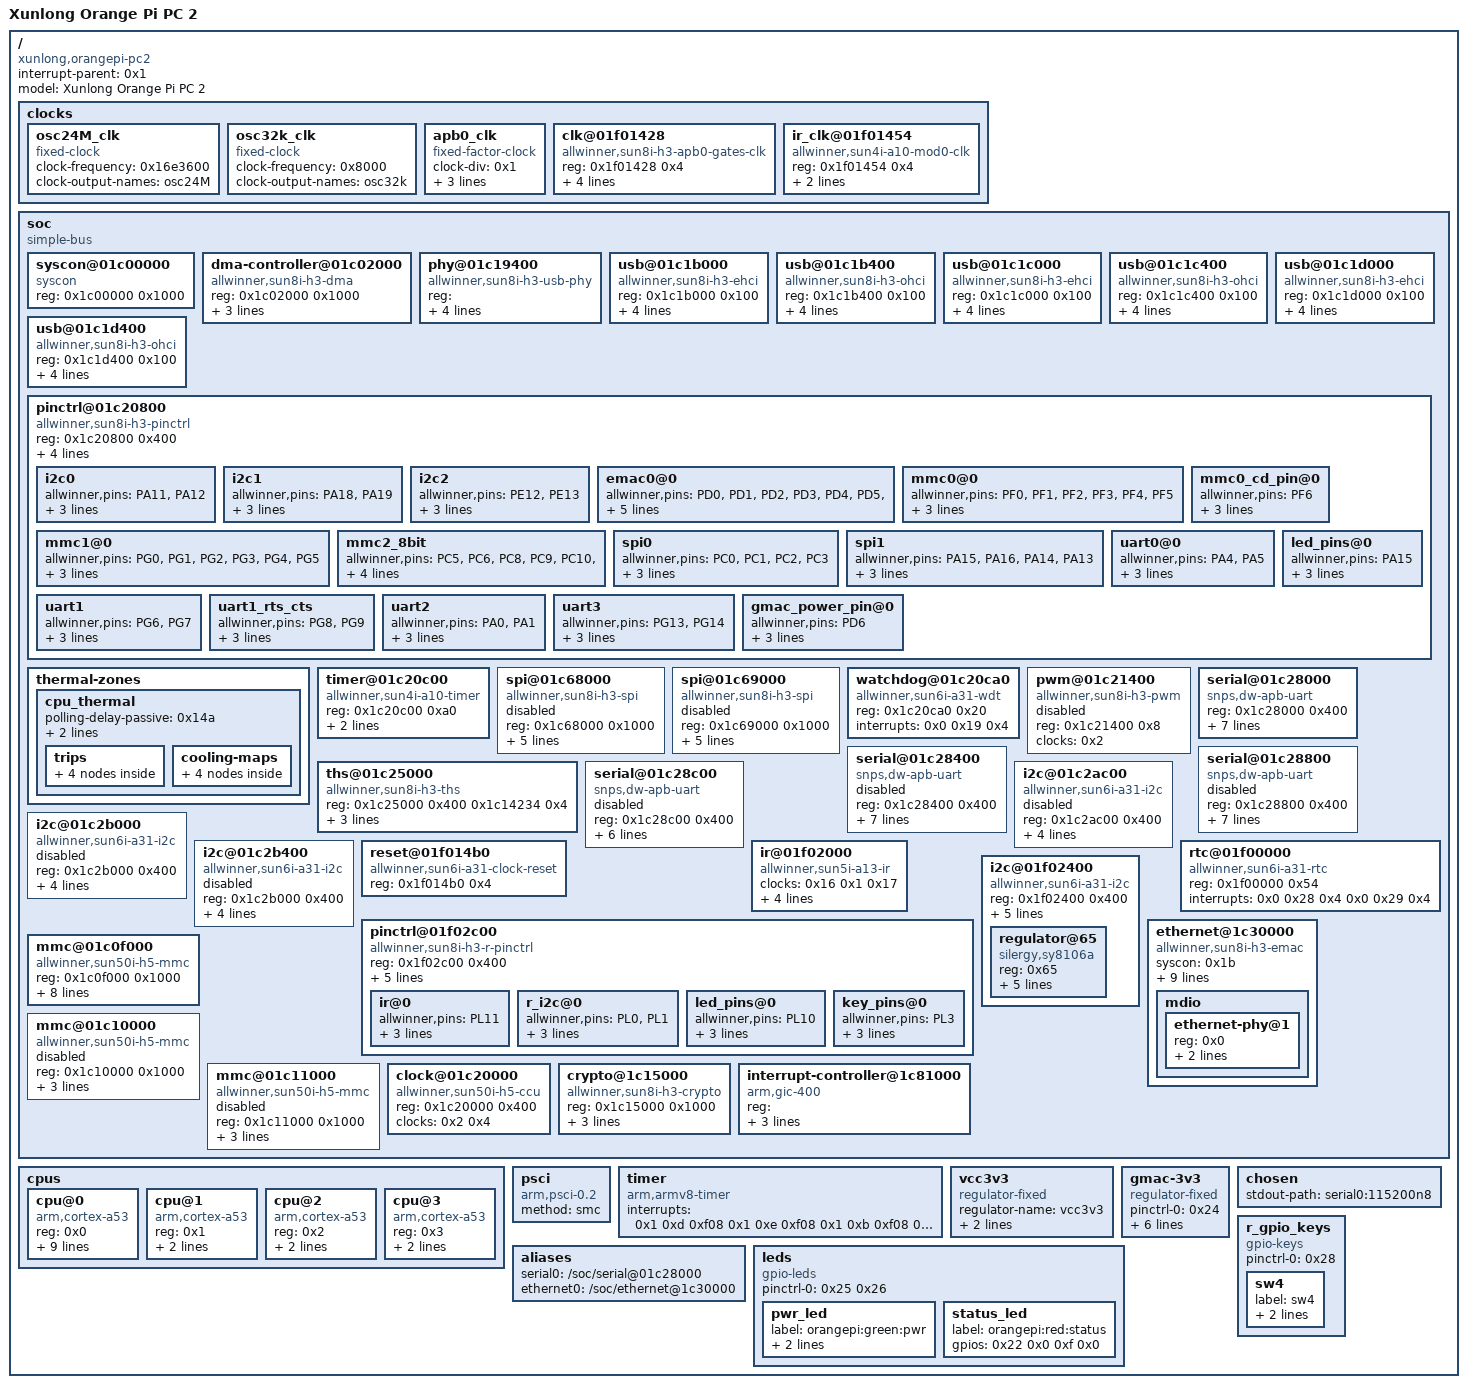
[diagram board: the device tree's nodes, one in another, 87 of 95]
/dts-v1/;

/ {
	#address-cells = <0x1>;
	#size-cells = <0x1>;
	interrupt-parent = <0x1>;
	model = "Xunlong Orange Pi PC 2";
	compatible = "xunlong,orangepi-pc2", "allwinner,sun50i-h5";

	clocks {
		#address-cells = <0x1>;
		#size-cells = <0x1>;
		ranges;

		osc24M_clk {
			#clock-cells = <0x0>;
			compatible = "fixed-clock";
			clock-frequency = <0x16e3600>;
			clock-output-names = "osc24M";
			linux,phandle = <0x2>;
			phandle = <0x2>;
		};

		osc32k_clk {
			#clock-cells = <0x0>;
			compatible = "fixed-clock";
			clock-frequency = <0x8000>;
			clock-output-names = "osc32k";
			linux,phandle = <0x4>;
			phandle = <0x4>;
		};

		apb0_clk {
			compatible = "fixed-factor-clock";
			#clock-cells = <0x0>;
			clock-div = <0x1>;
			clock-mult = <0x1>;
			clocks = <0x2>;
			clock-output-names = "apb0";
			linux,phandle = <0x3>;
			phandle = <0x3>;
		};

		clk@01f01428 {
			compatible = "allwinner,sun8i-h3-apb0-gates-clk", "allwinner,sun4i-a10-gates-clk";
			reg = <0x1f01428 0x4>;
			#clock-cells = <0x1>;
			clocks = <0x3>;
			clock-indices = <0x0 0x1 0x6>;
			clock-output-names = "apb0_pio", "apb0_ir", "apb0_i2c";
			linux,phandle = <0x16>;
			phandle = <0x16>;
		};

		ir_clk@01f01454 {
			compatible = "allwinner,sun4i-a10-mod0-clk";
			reg = <0x1f01454 0x4>;
			#clock-cells = <0x0>;
			clocks = <0x4 0x2>;
			clock-output-names = "ir";
			linux,phandle = <0x17>;
			phandle = <0x17>;
		};
	};

	soc {
		compatible = "simple-bus";
		#address-cells = <0x1>;
		#size-cells = <0x1>;
		ranges;

		syscon@01c00000 {
			compatible = "syscon", "allwinner,sun8i-h3-system-controller";
			reg = <0x1c00000 0x1000>;
			linux,phandle = <0x1b>;
			phandle = <0x1b>;
		};

		dma-controller@01c02000 {
			compatible = "allwinner,sun8i-h3-dma";
			reg = <0x1c02000 0x1000>;
			interrupts = <0x0 0x32 0x4>;
			clocks = <0x5 0x15>;
			resets = <0x5 0x6>;
			#dma-cells = <0x1>;
			linux,phandle = <0xd>;
			phandle = <0xd>;
		};

		phy@01c19400 {
			compatible = "allwinner,sun8i-h3-usb-phy";
			reg = <0x1c19400 0x2c 0x1c1a800 0x4 0x1c1b800 0x4 0x1c1c800 0x4 0x1c1d800 0x4>;
			reg-names = "phy_ctrl", "pmu0", "pmu1", "pmu2", "pmu3";
			clocks = <0x5 0x58 0x5 0x59 0x5 0x5a 0x5 0x5b>;
			clock-names = "usb0_phy", "usb1_phy", "usb2_phy", "usb3_phy";
			resets = <0x5 0x0 0x5 0x1 0x5 0x2 0x5 0x3>;
			reset-names = "usb0_reset", "usb1_reset", "usb2_reset", "usb3_reset";
			status = "okay";
			#phy-cells = <0x1>;
			dr_mode = "host";
			linux,phandle = <0x6>;
			phandle = <0x6>;
		};

		usb@01c1b000 {
			compatible = "allwinner,sun8i-h3-ehci", "generic-ehci";
			reg = <0x1c1b000 0x100>;
			interrupts = <0x0 0x4a 0x4>;
			clocks = <0x5 0x22 0x5 0x26>;
			resets = <0x5 0x13 0x5 0x17>;
			phys = <0x6 0x1>;
			phy-names = "usb";
			status = "okay";
		};

		usb@01c1b400 {
			compatible = "allwinner,sun8i-h3-ohci", "generic-ohci";
			reg = <0x1c1b400 0x100>;
			interrupts = <0x0 0x4b 0x4>;
			clocks = <0x5 0x22 0x5 0x26 0x5 0x5d>;
			resets = <0x5 0x13 0x5 0x17>;
			phys = <0x6 0x1>;
			phy-names = "usb";
			status = "okay";
		};

		usb@01c1c000 {
			compatible = "allwinner,sun8i-h3-ehci", "generic-ehci";
			reg = <0x1c1c000 0x100>;
			interrupts = <0x0 0x4c 0x4>;
			clocks = <0x5 0x23 0x5 0x27>;
			resets = <0x5 0x14 0x5 0x18>;
			phys = <0x6 0x2>;
			phy-names = "usb";
			status = "okay";
		};

		usb@01c1c400 {
			compatible = "allwinner,sun8i-h3-ohci", "generic-ohci";
			reg = <0x1c1c400 0x100>;
			interrupts = <0x0 0x4d 0x4>;
			clocks = <0x5 0x23 0x5 0x27 0x5 0x5e>;
			resets = <0x5 0x14 0x5 0x18>;
			phys = <0x6 0x2>;
			phy-names = "usb";
			status = "okay";
		};

		usb@01c1d000 {
			compatible = "allwinner,sun8i-h3-ehci", "generic-ehci";
			reg = <0x1c1d000 0x100>;
			interrupts = <0x0 0x4e 0x4>;
			clocks = <0x5 0x24 0x5 0x28>;
			resets = <0x5 0x15 0x5 0x19>;
			phys = <0x6 0x3>;
			phy-names = "usb";
			status = "okay";
		};

		usb@01c1d400 {
			compatible = "allwinner,sun8i-h3-ohci", "generic-ohci";
			reg = <0x1c1d400 0x100>;
			interrupts = <0x0 0x4f 0x4>;
			clocks = <0x5 0x24 0x5 0x28 0x5 0x5f>;
			resets = <0x5 0x15 0x5 0x19>;
			phys = <0x6 0x3>;
			phy-names = "usb";
			status = "okay";
		};

		pinctrl@01c20800 {
			compatible = "allwinner,sun8i-h3-pinctrl";
			reg = <0x1c20800 0x400>;
			interrupts = <0x0 0xb 0x4 0x0 0x11 0x4>;
			clocks = <0x5 0x36 0x2 0x4>;
			clock-names = "apb", "hosc", "losc";
			gpio-controller;
			#gpio-cells = <0x3>;
			interrupt-controller;
			#interrupt-cells = <0x3>;
			linux,phandle = <0x22>;
			phandle = <0x22>;

			i2c0 {
				allwinner,pins = "PA11", "PA12";
				allwinner,function = "i2c0";
				allwinner,drive = <0x0>;
				allwinner,pull = <0x0>;
				linux,phandle = <0x13>;
				phandle = <0x13>;
			};

			i2c1 {
				allwinner,pins = "PA18", "PA19";
				allwinner,function = "i2c1";
				allwinner,drive = <0x0>;
				allwinner,pull = <0x0>;
				linux,phandle = <0x14>;
				phandle = <0x14>;
			};

			i2c2 {
				allwinner,pins = "PE12", "PE13";
				allwinner,function = "i2c2";
				allwinner,drive = <0x0>;
				allwinner,pull = <0x0>;
				linux,phandle = <0x15>;
				phandle = <0x15>;
			};

			emac0@0 {
				allwinner,pins = "PD0", "PD1", "PD2", "PD3", "PD4", "PD5", "PD7", "PD8", "PD9", "PD10", "PD12", "PD13", "PD15", "PD16", "PD17";
				allwinner,function = "emac";
				allwinner,drive = <0x3>;
				allwinner,pull = <0x0>;
				linux,phandle = <0x1c>;
				phandle = <0x1c>;
			};

			mmc0@0 {
				allwinner,pins = "PF0", "PF1", "PF2", "PF3", "PF4", "PF5";
				allwinner,function = "mmc0";
				allwinner,drive = <0x2>;
				allwinner,pull = <0x0>;
				linux,phandle = <0x1f>;
				phandle = <0x1f>;
			};

			mmc0_cd_pin@0 {
				allwinner,pins = "PF6";
				allwinner,function = "gpio_in";
				allwinner,drive = <0x0>;
				allwinner,pull = <0x1>;
				linux,phandle = <0x20>;
				phandle = <0x20>;
			};

			mmc1@0 {
				allwinner,pins = "PG0", "PG1", "PG2", "PG3", "PG4", "PG5";
				allwinner,function = "mmc1";
				allwinner,drive = <0x2>;
				allwinner,pull = <0x0>;
			};

			mmc2_8bit {
				allwinner,pins = "PC5", "PC6", "PC8", "PC9", "PC10", "PC11", "PC12", "PC13", "PC14", "PC15", "PC16";
				allwinner,function = "mmc2";
				allwinner,drive = <0x2>;
				allwinner,pull = <0x0>;
			};

			spi0 {
				allwinner,pins = "PC0", "PC1", "PC2", "PC3";
				allwinner,function = "spi0";
				allwinner,drive = <0x0>;
				allwinner,pull = <0x0>;
				linux,phandle = <0xe>;
				phandle = <0xe>;
			};

			spi1 {
				allwinner,pins = "PA15", "PA16", "PA14", "PA13";
				allwinner,function = "spi1";
				allwinner,drive = <0x0>;
				allwinner,pull = <0x0>;
				linux,phandle = <0xf>;
				phandle = <0xf>;
			};

			uart0@0 {
				allwinner,pins = "PA4", "PA5";
				allwinner,function = "uart0";
				allwinner,drive = <0x0>;
				allwinner,pull = <0x0>;
				linux,phandle = <0x10>;
				phandle = <0x10>;
			};

			uart1 {
				allwinner,pins = "PG6", "PG7";
				allwinner,function = "uart1";
				allwinner,drive = <0x0>;
				allwinner,pull = <0x0>;
				linux,phandle = <0x11>;
				phandle = <0x11>;
			};

			uart1_rts_cts {
				allwinner,pins = "PG8", "PG9";
				allwinner,function = "uart1";
				allwinner,drive = <0x0>;
				allwinner,pull = <0x0>;
			};

			uart2 {
				allwinner,pins = "PA0", "PA1";
				allwinner,function = "uart2";
				allwinner,drive = <0x0>;
				allwinner,pull = <0x0>;
				linux,phandle = <0x12>;
				phandle = <0x12>;
			};

			uart3 {
				allwinner,pins = "PG13", "PG14";
				allwinner,function = "uart3";
				allwinner,drive = <0x0>;
				allwinner,pull = <0x0>;
			};

			led_pins@0 {
				allwinner,pins = "PA15";
				allwinner,function = "gpio_out";
				allwinner,drive = <0x0>;
				allwinner,pull = <0x0>;
				linux,phandle = <0x25>;
				phandle = <0x25>;
			};

			gmac_power_pin@0 {
				allwinner,pins = "PD6";
				allwinner,function = "gpio_out";
				allwinner,drive = <0x0>;
				allwinner,pull = <0x0>;
				linux,phandle = <0x24>;
				phandle = <0x24>;
			};
		};

		thermal-zones {

			cpu_thermal {
				polling-delay-passive = <0x14a>;
				polling-delay = <0x3e8>;
				thermal-sensors = <0x7 0x0>;

				trips {

					cpu_warm {
						temperature = <0xfde8>;
						hysteresis = <0x7d0>;
						type = "passive";
						linux,phandle = <0x8>;
						phandle = <0x8>;
					};

					cpu_hot {
						temperature = <0x124f8>;
						hysteresis = <0x7d0>;
						type = "passive";
						linux,phandle = <0xa>;
						phandle = <0xa>;
					};

					cpu_very_hot {
						temperature = <0x15f90>;
						hysteresis = <0x7d0>;
						type = "passive";
						linux,phandle = <0xb>;
						phandle = <0xb>;
					};

					cpu_crit {
						temperature = <0x19a28>;
						hysteresis = <0x7d0>;
						type = "critical";
						linux,phandle = <0xc>;
						phandle = <0xc>;
					};
				};

				cooling-maps {

					cpu_warm_limit_cpu {
						trip = <0x8>;
						cooling-device = <0x9 0xffffffff 0x10>;
					};

					cpu_hot_limit_cpu {
						trip = <0xa>;
						cooling-device = <0x9 0xc 0x12>;
					};

					cpu_very_hot_limit_cpu {
						trip = <0xb>;
						cooling-device = <0x9 0x10 0xffffffff>;
					};

					cpu_crit_limit_cpu {
						trip = <0xc>;
						cooling-device = <0x9 0x12 0xffffffff>;
					};
				};
			};
		};

		timer@01c20c00 {
			compatible = "allwinner,sun4i-a10-timer";
			reg = <0x1c20c00 0xa0>;
			interrupts = <0x0 0x12 0x4 0x0 0x13 0x4>;
			clocks = <0x2>;
		};

		spi@01c68000 {
			compatible = "allwinner,sun8i-h3-spi";
			reg = <0x1c68000 0x1000>;
			interrupts = <0x0 0x41 0x4>;
			clocks = <0x5 0x1e 0x5 0x52>;
			clock-names = "ahb", "mod";
			dmas = <0xd 0x17 0xd 0x17>;
			dma-names = "rx", "tx";
			pinctrl-names = "default";
			pinctrl-0 = <0xe>;
			resets = <0x5 0xf>;
			status = "disabled";
			#address-cells = <0x1>;
			#size-cells = <0x0>;
		};

		spi@01c69000 {
			compatible = "allwinner,sun8i-h3-spi";
			reg = <0x1c69000 0x1000>;
			interrupts = <0x0 0x42 0x4>;
			clocks = <0x5 0x1f 0x5 0x53>;
			clock-names = "ahb", "mod";
			dmas = <0xd 0x18 0xd 0x18>;
			dma-names = "rx", "tx";
			pinctrl-names = "default";
			pinctrl-0 = <0xf>;
			resets = <0x5 0x10>;
			status = "disabled";
			#address-cells = <0x1>;
			#size-cells = <0x0>;
		};

		watchdog@01c20ca0 {
			compatible = "allwinner,sun6i-a31-wdt";
			reg = <0x1c20ca0 0x20>;
			interrupts = <0x0 0x19 0x4>;
		};

		pwm@01c21400 {
			compatible = "allwinner,sun8i-h3-pwm";
			reg = <0x1c21400 0x8>;
			clocks = <0x2>;
			#pwm-cells = <0x3>;
			status = "disabled";
		};

		ths@01c25000 {
			#thermal-sensor-cells = <0x0>;
			compatible = "allwinner,sun8i-h3-ths";
			reg = <0x1c25000 0x400 0x1c14234 0x4>;
			interrupts = <0x0 0x1f 0x4>;
			resets = <0x5 0x2a>;
			reset-names = "ahb";
			clocks = <0x5 0x37 0x5 0x45>;
			clock-names = "ahb", "ths";
			linux,phandle = <0x7>;
			phandle = <0x7>;
		};

		serial@01c28000 {
			compatible = "snps,dw-apb-uart";
			reg = <0x1c28000 0x400>;
			interrupts = <0x0 0x0 0x4>;
			reg-shift = <0x2>;
			reg-io-width = <0x4>;
			clocks = <0x5 0x3e>;
			resets = <0x5 0x31>;
			dmas = <0xd 0x6 0xd 0x6>;
			dma-names = "rx", "tx";
			status = "okay";
			pinctrl-names = "default";
			pinctrl-0 = <0x10>;
		};

		serial@01c28400 {
			compatible = "snps,dw-apb-uart";
			reg = <0x1c28400 0x400>;
			interrupts = <0x0 0x1 0x4>;
			reg-shift = <0x2>;
			reg-io-width = <0x4>;
			clocks = <0x5 0x3f>;
			resets = <0x5 0x32>;
			dmas = <0xd 0x7 0xd 0x7>;
			dma-names = "rx", "tx";
			status = "disabled";
			pinctrl-names = "default";
			pinctrl-0 = <0x11>;
		};

		serial@01c28800 {
			compatible = "snps,dw-apb-uart";
			reg = <0x1c28800 0x400>;
			interrupts = <0x0 0x2 0x4>;
			reg-shift = <0x2>;
			reg-io-width = <0x4>;
			clocks = <0x5 0x40>;
			resets = <0x5 0x33>;
			dmas = <0xd 0x8 0xd 0x8>;
			dma-names = "rx", "tx";
			status = "disabled";
			pinctrl-names = "default";
			pinctrl-0 = <0x12>;
		};

		serial@01c28c00 {
			compatible = "snps,dw-apb-uart";
			reg = <0x1c28c00 0x400>;
			interrupts = <0x0 0x3 0x4>;
			reg-shift = <0x2>;
			reg-io-width = <0x4>;
			clocks = <0x5 0x41>;
			resets = <0x5 0x34>;
			dmas = <0xd 0x9 0xd 0x9>;
			dma-names = "rx", "tx";
			status = "disabled";
		};

		i2c@01c2ac00 {
			compatible = "allwinner,sun6i-a31-i2c";
			reg = <0x1c2ac00 0x400>;
			interrupts = <0x0 0x6 0x4>;
			clocks = <0x5 0x3b>;
			resets = <0x5 0x2e>;
			pinctrl-names = "default";
			pinctrl-0 = <0x13>;
			status = "disabled";
			#address-cells = <0x1>;
			#size-cells = <0x0>;
		};

		i2c@01c2b000 {
			compatible = "allwinner,sun6i-a31-i2c";
			reg = <0x1c2b000 0x400>;
			interrupts = <0x0 0x7 0x4>;
			clocks = <0x5 0x3c>;
			resets = <0x5 0x2f>;
			pinctrl-names = "default";
			pinctrl-0 = <0x14>;
			status = "disabled";
			#address-cells = <0x1>;
			#size-cells = <0x0>;
		};

		i2c@01c2b400 {
			compatible = "allwinner,sun6i-a31-i2c";
			reg = <0x1c2b000 0x400>;
			interrupts = <0x0 0x8 0x4>;
			clocks = <0x5 0x3d>;
			resets = <0x5 0x30>;
			pinctrl-names = "default";
			pinctrl-0 = <0x15>;
			status = "disabled";
			#address-cells = <0x1>;
			#size-cells = <0x0>;
		};

		rtc@01f00000 {
			compatible = "allwinner,sun6i-a31-rtc";
			reg = <0x1f00000 0x54>;
			interrupts = <0x0 0x28 0x4 0x0 0x29 0x4>;
		};

		reset@01f014b0 {
			reg = <0x1f014b0 0x4>;
			compatible = "allwinner,sun6i-a31-clock-reset";
			#reset-cells = <0x1>;
			linux,phandle = <0x18>;
			phandle = <0x18>;
		};

		ir@01f02000 {
			compatible = "allwinner,sun5i-a13-ir";
			clocks = <0x16 0x1 0x17>;
			clock-names = "apb", "ir";
			resets = <0x18 0x1>;
			interrupts = <0x0 0x25 0x4>;
			reg = <0x1f02000 0x40>;
			status = "okay";
			pinctrl-names = "default";
			pinctrl-0 = <0x19>;
		};

		pinctrl@01f02c00 {
			compatible = "allwinner,sun8i-h3-r-pinctrl";
			reg = <0x1f02c00 0x400>;
			interrupts = <0x0 0x2d 0x4>;
			clocks = <0x16 0x0 0x2 0x4>;
			clock-names = "apb", "hosc", "losc";
			resets = <0x18 0x0>;
			gpio-controller;
			#gpio-cells = <0x3>;
			interrupt-controller;
			#interrupt-cells = <0x3>;
			linux,phandle = <0x27>;
			phandle = <0x27>;

			ir@0 {
				allwinner,pins = "PL11";
				allwinner,function = "s_cir_rx";
				allwinner,drive = <0x0>;
				allwinner,pull = <0x0>;
				linux,phandle = <0x19>;
				phandle = <0x19>;
			};

			r_i2c@0 {
				allwinner,pins = "PL0", "PL1";
				allwinner,function = "s_twi";
				allwinner,drive = <0x0>;
				allwinner,pull = <0x0>;
				linux,phandle = <0x1a>;
				phandle = <0x1a>;
			};

			led_pins@0 {
				allwinner,pins = "PL10";
				allwinner,function = "gpio_out";
				allwinner,drive = <0x0>;
				allwinner,pull = <0x0>;
				linux,phandle = <0x26>;
				phandle = <0x26>;
			};

			key_pins@0 {
				allwinner,pins = "PL3";
				allwinner,function = "gpio_in";
				allwinner,drive = <0x0>;
				allwinner,pull = <0x0>;
				linux,phandle = <0x28>;
				phandle = <0x28>;
			};
		};

		i2c@01f02400 {
			compatible = "allwinner,sun6i-a31-i2c";
			reg = <0x1f02400 0x400>;
			interrupts = <0x0 0x2c 0x4>;
			pinctrl-names = "default";
			pinctrl-0 = <0x1a>;
			clocks = <0x16 0x6>;
			clock-frequency = <0x186a0>;
			resets = <0x18 0x6>;
			status = "okay";
			#address-cells = <0x1>;
			#size-cells = <0x0>;

			regulator@65 {
				compatible = "silergy,sy8106a";
				reg = <0x65>;
				regulator-min-microvolt = <0x10c8e0>;
				regulator-max-microvolt = <0x10c8e0>;
				regulator-ramp-delay = <0xc8>;
				regulator-boot-on;
				regulator-always-on;
				linux,phandle = <0x23>;
				phandle = <0x23>;
			};
		};

		ethernet@1c30000 {
			compatible = "allwinner,sun8i-h3-emac";
			syscon = <0x1b>;
			reg = <0x1c30000 0x104>;
			interrupts = <0x0 0x52 0x4>;
			resets = <0x5 0xc>;
			reset-names = "ahb";
			clocks = <0x5 0x1b>;
			clock-names = "ahb";
			#address-cells = <0x1>;
			#size-cells = <0x0>;
			status = "okay";
			pinctrl-names = "default";
			pinctrl-0 = <0x1c>;
			phy-supply = <0x1d>;
			phy-handle = <0x1e>;
			phy-mode = "rgmii";
			allwinner,leds-active-low;

			mdio {
				#address-cells = <0x1>;
				#size-cells = <0x0>;

				ethernet-phy@1 {
					reg = <0x0>;
					clocks = <0x5 0x43>;
					resets = <0x5 0x27>;
					linux,phandle = <0x1e>;
					phandle = <0x1e>;
				};
			};
		};

		mmc@01c0f000 {
			compatible = "allwinner,sun50i-h5-mmc", "allwinner,sun50i-a64-mmc", "allwinner,sun5i-a13-mmc";
			reg = <0x1c0f000 0x1000>;
			clocks = <0x5 0x16 0x5 0x47>;
			clock-names = "ahb", "mmc";
			resets = <0x5 0x7>;
			reset-names = "ahb";
			interrupts = <0x0 0x3c 0x4>;
			status = "okay";
			#address-cells = <0x1>;
			#size-cells = <0x0>;
			pinctrl-names = "default";
			pinctrl-0 = <0x1f 0x20>;
			vmmc-supply = <0x21>;
			bus-width = <0x4>;
			cd-gpios = <0x22 0x5 0x6 0x0>;
			cd-inverted;
		};

		mmc@01c10000 {
			compatible = "allwinner,sun50i-h5-mmc", "allwinner,sun50i-a64-mmc", "allwinner,sun5i-a13-mmc";
			reg = <0x1c10000 0x1000>;
			clocks = <0x5 0x17 0x5 0x4a>;
			clock-names = "ahb", "mmc";
			resets = <0x5 0x8>;
			reset-names = "ahb";
			interrupts = <0x0 0x3d 0x4>;
			status = "disabled";
			#address-cells = <0x1>;
			#size-cells = <0x0>;
		};

		mmc@01c11000 {
			compatible = "allwinner,sun50i-h5-mmc", "allwinner,sun50i-a64-mmc", "allwinner,sun5i-a13-mmc";
			reg = <0x1c11000 0x1000>;
			clocks = <0x5 0x18 0x5 0x4d>;
			clock-names = "ahb", "mmc";
			resets = <0x5 0x9>;
			reset-names = "ahb";
			interrupts = <0x0 0x3e 0x4>;
			status = "disabled";
			#address-cells = <0x1>;
			#size-cells = <0x0>;
		};

		clock@01c20000 {
			compatible = "allwinner,sun50i-h5-ccu", "allwinner,sun8i-h3-ccu";
			reg = <0x1c20000 0x400>;
			clocks = <0x2 0x4>;
			clock-names = "hosc", "losc";
			#clock-cells = <0x1>;
			#reset-cells = <0x1>;
			linux,phandle = <0x5>;
			phandle = <0x5>;
		};

		crypto@1c15000 {
			compatible = "allwinner,sun8i-h3-crypto";
			reg = <0x1c15000 0x1000>;
			interrupts = <0x0 0x50 0x4 0x0 0x5e 0x4>;
			interrupt-names = "ce_s", "ce_ns";
			resets = <0x5 0x5>;
			reset-names = "ahb";
			clocks = <0x5 0x14 0x5 0x51>;
			clock-names = "ahb1_ce", "mod";
			status = "okay";
		};

		interrupt-controller@1c81000 {
			compatible = "arm,gic-400";
			reg = <0x1c81000 0x1000 0x1c82000 0x2000 0x1c84000 0x2000 0x1c86000 0x2000>;
			interrupts = <0x1 0x9 0xf04>;
			interrupt-controller;
			#interrupt-cells = <0x3>;
			linux,phandle = <0x1>;
			phandle = <0x1>;
		};
	};

	cpus {
		#address-cells = <0x1>;
		#size-cells = <0x0>;

		cpu@0 {
			compatible = "arm,cortex-a53", "arm,armv8";
			device_type = "cpu";
			reg = <0x0>;
			enable-method = "psci";
			clocks = <0x5 0xe>;
			clock-latency = <0x3b9b0>;
			clock-frequency = <0x1c9c3800>;
			operating-points = <0x14dfc0 0x155cc0 0x148200 0x155cc0 0x13c680 0x147260 0x130b00 0x138800 0x12ad40 0x1339e0 0x124f80 0x12ebc0 0x119400 0x124f80 0x10d880 0x11da50 0x107ac0 0x11b340 0x101d00 0x118c30 0xf6180 0x10c8e0 0xea600 0x107ac0 0xe4840 0x102ca0 0xc7380 0xf4240 0xc15c0 0xf4240 0x9e340 0xecd10 0x75300 0xe57e0 0x3a980 0xe57e0 0x1d4c0 0xe57e0>;
			#cooling-cells = <0x2>;
			cooling-min-level = <0x0>;
			cooling-max-level = <0x12>;
			cpu0-supply = <0x23>;
			linux,phandle = <0x9>;
			phandle = <0x9>;
		};

		cpu@1 {
			compatible = "arm,cortex-a53", "arm,armv8";
			device_type = "cpu";
			reg = <0x1>;
			enable-method = "psci";
			clock-frequency = <0x1c9c3800>;
		};

		cpu@2 {
			compatible = "arm,cortex-a53", "arm,armv8";
			device_type = "cpu";
			reg = <0x2>;
			enable-method = "psci";
			clock-frequency = <0x1c9c3800>;
		};

		cpu@3 {
			compatible = "arm,cortex-a53", "arm,armv8";
			device_type = "cpu";
			reg = <0x3>;
			enable-method = "psci";
			clock-frequency = <0x1c9c3800>;
		};
	};

	psci {
		compatible = "arm,psci-0.2";
		method = "smc";
	};

	timer {
		compatible = "arm,armv8-timer";
		interrupts = <0x1 0xd 0xf08 0x1 0xe 0xf08 0x1 0xb 0xf08 0x1 0xa 0xf08>;
	};

	vcc3v3 {
		compatible = "regulator-fixed";
		regulator-name = "vcc3v3";
		regulator-min-microvolt = <0x325aa0>;
		regulator-max-microvolt = <0x325aa0>;
		linux,phandle = <0x21>;
		phandle = <0x21>;
	};

	gmac-3v3 {
		compatible = "regulator-fixed";
		pinctrl-names = "default";
		pinctrl-0 = <0x24>;
		regulator-name = "gmac-3v3";
		regulator-min-microvolt = <0x325aa0>;
		regulator-max-microvolt = <0x325aa0>;
		startup-delay-us = <0x186a0>;
		enable-active-high;
		gpio = <0x22 0x3 0x6 0x0>;
		linux,phandle = <0x1d>;
		phandle = <0x1d>;
	};

	aliases {
		serial0 = "/soc/serial@01c28000";
		ethernet0 = "/soc/ethernet@1c30000";
	};

	chosen {
		stdout-path = "serial0:115200n8";
	};

	leds {
		compatible = "gpio-leds";
		pinctrl-names = "default";
		pinctrl-0 = <0x25 0x26>;

		pwr_led {
			label = "orangepi:green:pwr";
			gpios = <0x27 0x0 0xa 0x0>;
			default-state = "on";
		};

		status_led {
			label = "orangepi:red:status";
			gpios = <0x22 0x0 0xf 0x0>;
		};
	};

	r_gpio_keys {
		compatible = "gpio-keys";
		pinctrl-names = "default";
		pinctrl-0 = <0x28>;

		sw4 {
			label = "sw4";
			linux,code = <0x100>;
			gpios = <0x27 0x0 0x3 0x1>;
		};
	};
};
